AUTOSAR XML (schema 00046)
standard types defined: uint8
package /DataTypes/ApplicationDataTypes
  app type AdtName1: category=VALUE
package /DataTypes/ImplementationDataTypes
  impl type IdtName1: category=VALUE, base-type=uint8
package /SoftwareTypes/ComponentTypes
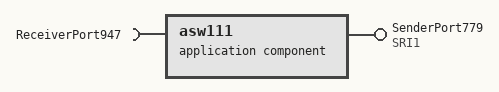
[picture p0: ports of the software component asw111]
  application sw component type asw111
    provide port SenderPort779: provided-interface=SRI1
    require port ReceiverPort947
  composition sw component type c1
    component c11: type=c11
  composition sw component type c11
    component asw111: type=asw111
  composition sw component type ecu1aliasnameEcuComp
    component c1: type=c1
package /SoftwareTypes/Interfaces
  sender receiver interface SRI1
    data DE1: type=IdtName1
package /System
  system HEV: category=ECU_SYSTEM_DESCRIPTION
    system mapping Mappings117
      sw-mappings:
        swc to ecu mapping SwHwMapping190608: component=ecu1aliasnameEcuComp.c1.c11.asw111, ecu-instance=ecu1aliasname
    root-software-compositions:
      root sw composition prototype ecu1aliasnameEcuComp: software-composition=ecu1aliasnameEcuComp  # r1longname
package /Topology/HardwareComponents
  ecu instance ecu1aliasname: sleep-mode-supported=false, wake-up-over-bus-supported=false  # ecu1longname
